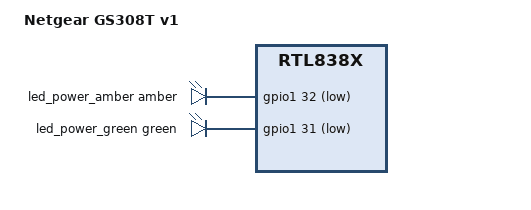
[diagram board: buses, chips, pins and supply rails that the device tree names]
// SPDX-License-Identifier: GPL-2.0-or-later

#include "rtl8380_netgear_gigabit.dtsi"

#include <dt-bindings/leds/common.h>
#include <dt-bindings/leds/rtl838x-leds.h>

/ {
	compatible = "netgear,gs308t-v1", "realtek,rtl838x-soc";
	model = "Netgear GS308T v1";

	aliases {
		led-boot = &led_power_green;
		led-failsafe = &led_power_amber;
		led-running = &led_power_green;
		led-upgrade = &led_power_amber;
	};

	leds {
		compatible = "gpio-leds";

		led_power_amber: led-0 {
			color = <LED_COLOR_ID_AMBER>;
			function = LED_FUNCTION_POWER;
			gpios = <&gpio1 32 GPIO_ACTIVE_LOW>;
		};

		led_power_green: led-1 {
			color = <LED_COLOR_ID_GREEN>;
			function = LED_FUNCTION_POWER;
			gpios = <&gpio1 31 GPIO_ACTIVE_LOW>;
		};
	};

	port_leds {
		compatible = "realtek,rtl838x-leds";

		// two leds per port
		leds-per-port = <RTL838x_NUM_LEDS_TWO_LEDS>;

		// serial control mode
		led-control = <RTL838x_LEDS_CONTROL_SERIAL>;

		// blink all leds on power-on
		power-on-blink;

		// beware - due to how the leds are wired (back-to-back), only one of
		// them can be active at any given time. if both would light up,
		// both will go off.
		// this limits the number of useful combinations.
		led_green: led-0-mode = <RTL838x_LEDS_MODE_LINK_ACT_1G>;
		led_amber: led-1-mode = <RTL838x_LEDS_MODE_LINK_ACT_100M_10M>;
	};
};

&firmware {
	openwrt,ih-magic = <0x4e474335>;
};
